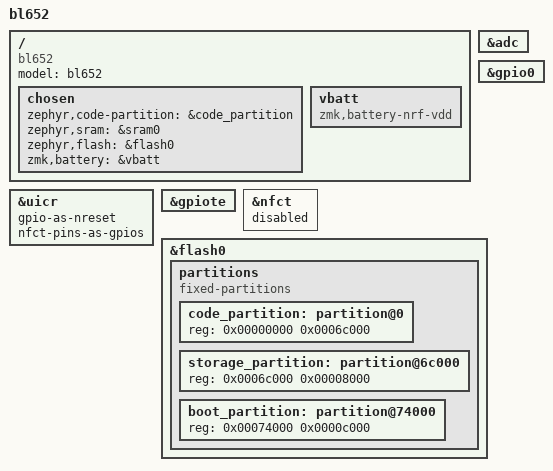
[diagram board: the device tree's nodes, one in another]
/*
 * Copyright (c) 2024 The ZMK Contributors
 *
 * SPDX-License-Identifier: MIT
 */

/dts-v1/;
#include <nordic/nrf52832_qfaa.dtsi>

#include <dt-bindings/led/led.h>
#include <dt-bindings/zmk/matrix_transform.h>

/ {
    model = "bl652";
    compatible = "bl652";

    chosen {
        zephyr,code-partition = &code_partition;
        zephyr,sram = &sram0;
        zephyr,flash = &flash0;
        zmk,battery = &vbatt;
    };

    vbatt: vbatt {
        compatible = "zmk,battery-nrf-vdd";
    };
};

&adc {
    status = "okay";
};

&uicr {
	gpio-as-nreset;
	nfct-pins-as-gpios;
};

&gpiote {
    status = "okay";
};

&gpio0 {
    status = "okay";
};

&nfct {
	status = "disabled";
};

&flash0 {
    /*
     * For more information, see:
     * http://docs.zephyrproject.org/latest/devices/dts/flash_partitions.html
     */
    partitions {
        compatible = "fixed-partitions";
        #address-cells = <1>;
        #size-cells = <1>;

        code_partition: partition@0 {
            reg = <0x00000000 0x0006c000>;
        };

        /*
         * The flash starting at 0x0006c000 and ending at
         * 0x00073fff is reserved for use by the application.
         */

        /*
         * Storage partition will be used by FCB/LittleFS/NVS
         * if enabled.
         */
        storage_partition: partition@6c000 {
            reg = <0x0006c000 0x00008000>;
        };

        boot_partition: partition@74000 {
            reg = <0x00074000 0x0000c000>;
        };
    };
};
